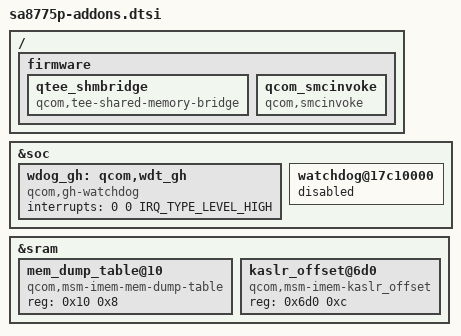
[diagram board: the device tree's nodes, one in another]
// SPDX-License-Identifier: BSD-3-Clause
/*
 * Copyright (c) 2024 Qualcomm Innovation Center, Inc. All rights reserved.
 */

/ {
	firmware {
		qtee_shmbridge {
			compatible = "qcom,tee-shared-memory-bridge";
		};

		qcom_smcinvoke {
			compatible = "qcom,smcinvoke";
		};
	};

};

&soc {
	wdog_gh: qcom,wdt_gh {
		compatible = "qcom,gh-watchdog";
		interrupts = <0 0 IRQ_TYPE_LEVEL_HIGH>;
	};

	watchdog@17c10000 {
		status = "disabled";
	};
};

&sram {
	mem_dump_table@10 {
		compatible = "qcom,msm-imem-mem-dump-table";
		reg = <0x10 0x8>;
	};

	kaslr_offset@6d0 {
		compatible = "qcom,msm-imem-kaslr_offset";
		reg = <0x6d0 0xc>;
	};
};
